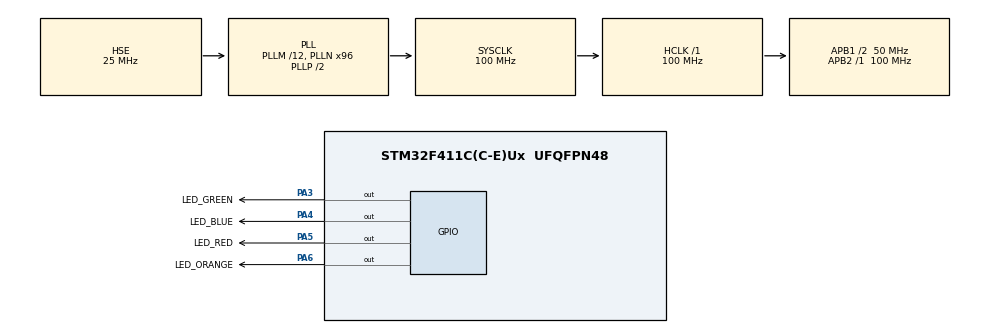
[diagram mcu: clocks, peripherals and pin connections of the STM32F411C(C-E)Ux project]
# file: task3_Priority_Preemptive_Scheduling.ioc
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FREERTOS.Tasks01=defaultTask,24,128,StartDefaultTask,Default,NULL,Dynamic,NULL,NULL;FlashGreenLedTa,24,128,FlashGreenLed,Default,NULL,Dynamic,NULL,NULL;FlashRedLedTask,32,128,FlashRedLed,Default,NULL,Dynamic,NULL,NULL
FREERTOS.configUSE_NEWLIB_REENTRANT=1
Mcu.Family=STM32F4
Mcu.Name=STM32F411C(C-E)Ux
Mcu.Package=UFQFPN48
NVIC.PriorityGroup=NVIC_PRIORITYGROUP_4
NVIC.TIM4_IRQn=true\:15\:0\:false\:false\:true\:false\:false\:true\:true
NVIC.TimeBase=TIM4_IRQn
NVIC.TimeBaseIP=TIM4
PA13.Mode=Serial_Wire
PA13.Signal=SYS_JTMS-SWDIO
PA14.Mode=Serial_Wire
PA14.Signal=SYS_JTCK-SWCLK
PA3.GPIO_Label=LED_GREEN
PA3.Signal=GPIO_Output
PA4.GPIO_Label=LED_BLUE
PA4.Signal=GPIO_Output
PA5.GPIO_Label=LED_RED
PA5.Signal=GPIO_Output
PA6.GPIO_Label=LED_ORANGE
PA6.Signal=GPIO_Output
PH0\ -\ OSC_IN.Mode=HSE-External-Oscillator
PH0\ -\ OSC_IN.Signal=RCC_OSC_IN
PH1\ -\ OSC_OUT.Mode=HSE-External-Oscillator
PH1\ -\ OSC_OUT.Signal=RCC_OSC_OUT
ProjectManager.HeapSize=0x200
ProjectManager.StackSize=0x400
ProjectManager.TargetToolchain=STM32CubeIDE
RCC.48MHZClocksFreq_Value=50000000
RCC.AHBFreq_Value=100000000
RCC.APB1CLKDivider=RCC_HCLK_DIV2
RCC.APB1Freq_Value=50000000
RCC.APB1TimFreq_Value=100000000
RCC.APB2Freq_Value=100000000
RCC.APB2TimFreq_Value=100000000
RCC.CortexFreq_Value=100000000
RCC.HCLKFreq_Value=100000000
RCC.HSE_VALUE=25000000
RCC.HSI_VALUE=16000000
RCC.LSE_VALUE=32768
RCC.PLLM=12
RCC.PLLN=96
RCC.PLLSourceVirtual=RCC_PLLSOURCE_HSE
RCC.SYSCLKFreq_VALUE=100000000
RCC.SYSCLKSource=RCC_SYSCLKSOURCE_PLLCLK
RCC.VCOOutputFreq_Value=200000000
VP_FREERTOS_VS_CMSIS_V2.Mode=CMSIS_V2
VP_SYS_VS_tim4.Mode=TIM4
board=custom

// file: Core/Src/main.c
/* USER CODE BEGIN Header */
/**
  ******************************************************************************
  * @file           : main.c
  * @brief          : Main program body
  ******************************************************************************
  * @attention
  *
  * Copyright (c) 2024 STMicroelectronics.
  * All rights reserved.
  *
  * This software is licensed under terms that can be found in the LICENSE file
  * in the root directory of this software component.
  * If no LICENSE file comes with this software, it is provided AS-IS.
  *
  ******************************************************************************
  */
/* USER CODE END Header */
#include "main.h"
#include "cmsis_os.h"

/* Definitions for defaultTask */
osThreadId_t defaultTaskHandle;
const osThreadAttr_t defaultTask_attributes = {
  .name = "defaultTask",
  .stack_size = 128 * 4,
  .priority = (osPriority_t) osPriorityNormal,
};
/* Definitions for FlashGreenLedTa */
osThreadId_t FlashGreenLedTaHandle;
const osThreadAttr_t FlashGreenLedTa_attributes = {
  .name = "FlashGreenLedTa",
  .stack_size = 128 * 4,
  .priority = (osPriority_t) osPriorityNormal,
};
/* Definitions for FlashRedLedTask */
osThreadId_t FlashRedLedTaskHandle;
const osThreadAttr_t FlashRedLedTask_attributes = {
  .name = "FlashRedLedTask",
  .stack_size = 128 * 4,
  .priority = (osPriority_t) osPriorityAboveNormal,
};

void SystemClock_Config(void);
static void MX_GPIO_Init(void);
void StartDefaultTask(void *argument);
void FlashGreenLed(void *argument);
void FlashRedLed(void *argument);

int main(void)
{

  /* MCU Configuration--------------------------------------------------------*/

  /* Reset of all peripherals, Initializes the Flash interface and the Systick. */
  HAL_Init();

  /* Configure the system clock */
  SystemClock_Config();

  /* Initialize all configured peripherals */
  MX_GPIO_Init();

  /* Init scheduler */
  osKernelInitialize();

  /* Create the thread(s) */
  /* creation of defaultTask */
  defaultTaskHandle = osThreadNew(StartDefaultTask, NULL, &defaultTask_attributes);

  /* creation of FlashGreenLedTa */
  FlashGreenLedTaHandle = osThreadNew(FlashGreenLed, NULL, &FlashGreenLedTa_attributes);

  /* creation of FlashRedLedTask */
  FlashRedLedTaskHandle = osThreadNew(FlashRedLed, NULL, &FlashRedLedTask_attributes);

  /* Start scheduler */
  osKernelStart();

  /* We should never get here as control is now taken by the scheduler */

  /* Infinite loop */
  while (1)
  {

  }
}

void SystemClock_Config(void)
{
  RCC_OscInitTypeDef RCC_OscInitStruct = {0};
  RCC_ClkInitTypeDef RCC_ClkInitStruct = {0};

  /** Configure the main internal regulator output voltage
  */
  __HAL_RCC_PWR_CLK_ENABLE();
  __HAL_PWR_VOLTAGESCALING_CONFIG(PWR_REGULATOR_VOLTAGE_SCALE1);

  /** Initializes the RCC Oscillators according to the specified parameters
  * in the RCC_OscInitTypeDef structure.
  */
  RCC_OscInitStruct.OscillatorType = RCC_OSCILLATORTYPE_HSE;
  RCC_OscInitStruct.HSEState = RCC_HSE_ON;
  RCC_OscInitStruct.PLL.PLLState = RCC_PLL_ON;
  RCC_OscInitStruct.PLL.PLLSource = RCC_PLLSOURCE_HSE;
  RCC_OscInitStruct.PLL.PLLM = 12;
  RCC_OscInitStruct.PLL.PLLN = 96;
  RCC_OscInitStruct.PLL.PLLP = RCC_PLLP_DIV2;
  RCC_OscInitStruct.PLL.PLLQ = 4;
  if (HAL_RCC_OscConfig(&RCC_OscInitStruct) != HAL_OK)
  {
    Error_Handler();
  }

  /** Initializes the CPU, AHB and APB buses clocks
  */
  RCC_ClkInitStruct.ClockType = RCC_CLOCKTYPE_HCLK|RCC_CLOCKTYPE_SYSCLK
                              |RCC_CLOCKTYPE_PCLK1|RCC_CLOCKTYPE_PCLK2;
  RCC_ClkInitStruct.SYSCLKSource = RCC_SYSCLKSOURCE_PLLCLK;
  RCC_ClkInitStruct.AHBCLKDivider = RCC_SYSCLK_DIV1;
  RCC_ClkInitStruct.APB1CLKDivider = RCC_HCLK_DIV2;
  RCC_ClkInitStruct.APB2CLKDivider = RCC_HCLK_DIV1;

  if (HAL_RCC_ClockConfig(&RCC_ClkInitStruct, FLASH_LATENCY_3) != HAL_OK)
  {
    Error_Handler();
  }
}

static void MX_GPIO_Init(void)
{
  GPIO_InitTypeDef GPIO_InitStruct = {0};

  /* GPIO Ports Clock Enable */
  __HAL_RCC_GPIOH_CLK_ENABLE();
  __HAL_RCC_GPIOA_CLK_ENABLE();

  /*Configure GPIO pin Output Level */
  HAL_GPIO_WritePin(GPIOA, LED_GREEN_Pin|LED_BLUE_Pin|LED_RED_Pin|LED_ORANGE_Pin, GPIO_PIN_RESET);

  /*Configure GPIO pins : LED_GREEN_Pin LED_BLUE_Pin LED_RED_Pin LED_ORANGE_Pin */
  GPIO_InitStruct.Pin = LED_GREEN_Pin|LED_BLUE_Pin|LED_RED_Pin|LED_ORANGE_Pin;
  GPIO_InitStruct.Mode = GPIO_MODE_OUTPUT_PP;
  GPIO_InitStruct.Pull = GPIO_NOPULL;
  GPIO_InitStruct.Speed = GPIO_SPEED_FREQ_LOW;
  HAL_GPIO_Init(GPIOA, &GPIO_InitStruct);

}

void StartDefaultTask(void *argument)
{
  for(;;)
  {
    osDelay(1);
  }
}

void FlashGreenLed(void *argument)
{
  /* USER CODE BEGIN FlashGreenLed */
  /* Infinite loop */
	for(;;)
	{
		HAL_GPIO_WritePin(LED_BLUE_GPIO_Port, LED_BLUE_Pin, SET);
		// 4 second
		for (int i = 0; i < 160; ++i)
		{
			HAL_GPIO_TogglePin(LED_GREEN_GPIO_Port, LED_GREEN_Pin);
			HAL_Delay(25);
		}

		HAL_GPIO_WritePin(LED_GREEN_GPIO_Port, LED_GREEN_Pin, RESET);
		HAL_GPIO_WritePin(LED_BLUE_GPIO_Port, LED_BLUE_Pin, RESET);

		osDelay(6000);
	}
  /* USER CODE END FlashGreenLed */
}

void FlashRedLed(void *argument)
{
  /* USER CODE BEGIN FlashRedLed */
  /* Infinite loop */
	for(;;)
	{
		HAL_GPIO_WritePin(LED_ORANGE_GPIO_Port, LED_ORANGE_Pin, SET);

		for (int i = 0; i < 20; ++i)
		{
			HAL_GPIO_TogglePin(LED_RED_GPIO_Port, LED_RED_Pin);
			HAL_Delay(25);
		}

		HAL_GPIO_WritePin(LED_RED_GPIO_Port, LED_RED_Pin, RESET);
		HAL_GPIO_WritePin(LED_ORANGE_GPIO_Port, LED_ORANGE_Pin, RESET);

		osDelay(1500);
	}
  /* USER CODE END FlashRedLed */
}

void HAL_TIM_PeriodElapsedCallback(TIM_HandleTypeDef *htim)
{
  if (htim->Instance == TIM4) {
    HAL_IncTick();
  }
}

void Error_Handler(void)
{
  __disable_irq();
  while (1)
  {
  }
}
